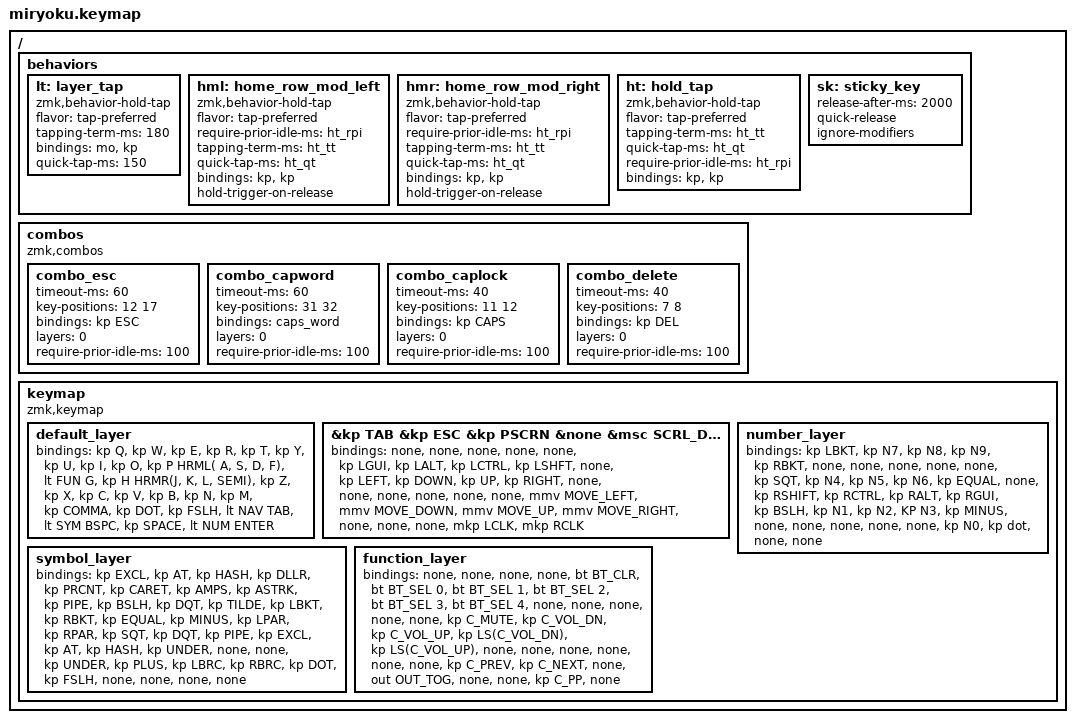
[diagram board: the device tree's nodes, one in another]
#define ZMK_POINTING_DEFAULT_MOVE_VAL 800
#define ZMK_POINTING_DEFAULT_SCRL_VAL 10

#include <behaviors.dtsi>
#include <dt-bindings/zmk/keys.h>
#include <dt-bindings/zmk/bt.h>
#include <dt-bindings/zmk/outputs.h>
#include <dt-bindings/zmk/pointing.h>

// Define layers
#define NAV 1
#define NUM  2
#define SYM 3
#define FUN 4

// Home row mods macro
#define HRML(k1,k2,k3,k4) &hml LGUI k1  &hml LALT k2  &hml LCTRL k3  &hml LSHFT k4
#define HRMR(k1,k2,k3,k4) &hmr RSHFT k1  &hmr RCTRL k2  &hmr RALT k3  &hmr RGUI k4

#define ht_tt 200
#define ht_qt 125
#define ht_rpi 100

/ {
    behaviors {
        lt: layer_tap {
            compatible = "zmk,behavior-hold-tap";
            #binding-cells = <2>;
            flavor = "tap-preferred";
            tapping-term-ms = <180>;
            bindings = <&mo>, <&kp>;
            quick-tap-ms = <150>;
        };

        hml: home_row_mod_left {
            compatible = "zmk,behavior-hold-tap";
            #binding-cells = <2>;
            flavor = "tap-preferred";
            require-prior-idle-ms = <ht_rpi>;
            tapping-term-ms = <ht_tt>;
            quick-tap-ms = <ht_qt>;
            bindings = <&kp>, <&kp>;
            hold-trigger-on-release;
        };
        hmr: home_row_mod_right {
            compatible = "zmk,behavior-hold-tap";
            #binding-cells = <2>;
            flavor = "tap-preferred";
            require-prior-idle-ms = <ht_rpi>;
            tapping-term-ms = <ht_tt>;
            quick-tap-ms = <ht_qt>;
            bindings = <&kp>, <&kp>;
            hold-trigger-on-release;
        };
        //I used for prior version of mod tap
        ht: hold_tap {
            compatible = "zmk,behavior-hold-tap";
            #binding-cells = <2>;
            flavor = "tap-preferred";
            tapping-term-ms = <ht_tt>;
            quick-tap-ms = <ht_qt>;
            require-prior-idle-ms = <ht_rpi>;
            bindings = <&kp>, <&kp>;
        };
        sk: sticky_key {
            release-after-ms = <2000>;
            quick-release;
            ignore-modifiers;
        };
    };
    combos {
        compatible = "zmk,combos";
        combo_esc {
            timeout-ms = <60>;
            key-positions = <12 17>;
            bindings = <&kp ESC>;
            layers = <0>;
            require-prior-idle-ms = <100>;
        };
        combo_capword{
            timeout-ms = <60>;
            key-positions = <31 32>;
            bindings = <&caps_word>;
            layers = <0>;
            require-prior-idle-ms = <100>;
        };
        combo_caplock {
            timeout-ms = <40>;
            key-positions = <11 12>;
            bindings = <&kp CAPS>;
            layers = <0>;
            require-prior-idle-ms = <100>;
        };
        combo_delete{
            timeout-ms = <40>;
            key-positions = <7 8>;
            bindings = <&kp DEL>;
            layers = <0>;
            require-prior-idle-ms = <100>;
        };
    };

    keymap {
        compatible = "zmk,keymap";
        default_layer {
            bindings = <
                //╭──────────┬──────────┬──────────┬──────────┬──────────╮   ╭──────────┬──────────┬──────────┬──────────┬──────────╮
                //│  Q       │  W       │  E       │  R       │  T       │   │  Y       │  U       │  I       │  O       │   P      │
                    &kp Q      &kp W      &kp E      &kp R      &kp T          &kp Y      &kp U     &kp I        &kp O      &kp P 
                //├──────────┼──────────┼──────────┼──────────┼──────────┤   ├──────────┼──────────┼──────────┼──────────┼──────────┤
                //│  A       │  S       │  D       │  F       │  G       │   │  H       │  J       │  K       │  L       │  ; :     │
                    HRML( A,     S,        D,           F)      &lt FUN G     &kp H      HRMR(J,      K,        L,         SEMI)
                //├──────────┼──────────┼──────────┼──────────┼──────────┤   ├──────────┼──────────┼──────────┼──────────┼──────────┤
                //│  Z       │  X       │  C       │  V       │  B       │   │  N       │  M       │ , <      │ . >      │ / ?      │
                    &kp Z       &kp X      &kp C      &kp V      &kp B          &kp N      &kp M      &kp COMMA  &kp DOT    &kp FSLH
                //╰──────────┴──────────┴──────────┼──────────┼──────────┤   ├──────────┼──────────┼──────────┴──────────┴──────────╯
                                                   &lt NAV TAB &lt SYM BSPC   &kp SPACE &lt NUM ENTER
                //                                 ╰──────────┴──────────╯   ╰──────────┴──────────╯
            >;
        };
         
                   &kp LA(TAB)  &kp TAB    &kp ESC   &kp PSCRN  &none        &msc SCRL_DOWN &kp PG_DN &kp PG_UP &msc SCRL_UP &kp DEL
        navigation_layer {
            bindings = <
                //╭──────────┬──────────┬──────────┬──────────┬──────────╮   ╭──────────┬──────────┬──────────┬──────────┬──────────╮
                //│ ALT+TAB  │   TAB    │   ESC    │   PTS    │          │   │  HOME    │  PG_DN   │ PG_UP    │  S_UP    │   DEL    │
                    &none       &none      &none      &none     &none          
                //├──────────┼──────────┼──────────┼──────────┼──────────┤   ├──────────┼──────────┼──────────┼──────────┼──────────┤
                //│          │          │          │          │          │   │   left   │  down    │   up     │  right   │          │
                    &kp LGUI   &kp LALT   &kp LCTRL  &kp LSHFT  &none          &kp LEFT   &kp DOWN   &kp UP     &kp RIGHT   &none
                //├──────────┼──────────┼──────────┼──────────┼──────────┤   ├──────────┼──────────┼──────────┼──────────┼──────────┤
                //│          │          │          │          │          │   │ m left   │ m down   │  m up    │ m  right │  ENTER   │
                     &none      &none      &none      &none       &none  &mmv MOVE_LEFT &mmv MOVE_DOWN &mmv MOVE_UP &mmv MOVE_RIGHT  &none
                //╰──────────┴──────────┴──────────┼──────────┼──────────┤   ├──────────┼──────────┼──────────┴──────────┴──────────╯
                                                      &none       &none        &mkp LCLK  &mkp RCLK
            //                                     ╰──────────┴──────────╯   ╰──────────┴──────────╯
            >;
        };       
        
        number_layer {
            bindings = <
                //╭──────────┬──────────┬──────────┬──────────┬──────────╮   ╭──────────┬──────────┬──────────┬──────────┬──────────╮
                //│    [     │    7     │    8     │    9     │    ]     │   │          │          │          │          │          │
                    &kp LBKT    &kp N7     &kp N8     &kp N9    &kp RBKT        &none      &none      &none      &none      &none
                //├──────────┼──────────┼──────────┼──────────┼──────────┤   ├──────────┼──────────┼──────────┼──────────┼──────────┤
                //│    '     │    4     │    5     │    6     │    =     │   │          │          │          │          │          │
                    &kp SQT     &kp N4     &kp N5     &kp N6    &kp EQUAL       &none    &kp RSHIFT  &kp RCTRL  &kp RALT   &kp RGUI
                //├──────────┼──────────┼──────────┼──────────┼──────────┤   ├──────────┼──────────┼──────────┼──────────┼──────────┤
                //│     \    │    1     │    2     │    3     │    -     │   │          │          │          │          │          │
                    &kp BSLH    &kp N1     &kp N2     &KP N3    &kp MINUS       &none      &none      &none      &none      &none
                //╰──────────┴──────────┴──────────┼──────────┼──────────┤   ├──────────┼──────────┼──────────┴──────────┴──────────╯
                                                     &kp N0     &kp dot         &none       &none
                //                                 ╰──────────┴──────────╯   ╰──────────┴──────────╯
            >;
        };

        symbol_layer {
            bindings = <
                //╭──────────┬──────────┬──────────┬──────────┬──────────╮   ╭──────────┬──────────┬──────────┬──────────┬──────────╮
                //│     !    │    @     │    #     │    $     │    %     │   │    ^     │    &     │     *    │    |     │    \     │
                    &kp EXCL   &kp AT     &kp HASH   &kp DLLR   &kp PRCNT      &kp CARET  &kp AMPS   &kp ASTRK  &kp PIPE    &kp BSLH
                //├──────────┼──────────┼──────────┼──────────┼──────────┤   ├──────────┼──────────┼──────────┼──────────┼──────────┤
                //│    `     │    ~     │    [     │    ]     │    =     │   │    -     │    (     │    )     │    '     │    "     │
                    &kp DQT     &kp TILDE  &kp LBKT   &kp RBKT   &kp EQUAL      &kp MINUS  &kp LPAR   &kp RPAR   &kp SQT    &kp DQT //├──────────┼──────────┼──────────┼──────────┼──────────┤   ├──────────┼──────────┼──────────┼──────────┼──────────┤
                //│          │          │          │          │    _     │   │    +     │    {     │    }     │    .     │    /     │
                    &kp PIPE   &kp EXCL    &kp AT    &kp HASH   &kp UNDER       &none      &none    &kp UNDER      &kp PLUS   &kp LBRC    &kp RBRC   &kp DOT    &kp FSLH
                //╰──────────┴──────────┴──────────┼──────────┼──────────┤   ├──────────┼──────────┼──────────┴──────────┴──────────╯
                                                       &none     &none         &none       &none
                //                                 ╰──────────┴──────────╯   ╰──────────┴──────────╯
            >;
        };

        function_layer {
            bindings = <
                //╭──────────┬──────────┬──────────┬──────────┬──────────╮   ╭──────────┬──────────┬──────────┬──────────┬──────────╮
                //│          │          │          │          │          │   │          │          │          │          │          │
                    &none       &none      &none      &none    &bt BT_CLR  &bt BT_SEL 0 &bt BT_SEL 1 &bt BT_SEL 2 &bt BT_SEL 3 &bt BT_SEL 4
                //├──────────┼──────────┼──────────┼──────────┼──────────┤   ├──────────┼──────────┼──────────┼──────────┼──────────┤
                //│          │          │          │          │          │   │          │          │          │          │          │
                     &none      &none     &none       &none      &none       &kp C_MUTE &kp C_VOL_DN &kp C_VOL_UP &kp LS(C_VOL_DN) &kp LS(C_VOL_UP)
                //├──────────┼──────────┼──────────┼──────────┼──────────┤   ├──────────┼──────────┼──────────┼──────────┼──────────┤
                //│          │          │          │          │          │   │          │          │          │          │          │
                    &none       &none      &none      &none      &none         &none    &kp C_PREV  &kp C_NEXT  &none     &out OUT_TOG
                //╰──────────┴──────────┴──────────┼──────────┼──────────┤   ├──────────┼──────────┼──────────┴──────────┴──────────╯
                                                     &none      &none          &kp C_PP    &none 
                //                                 ╰──────────┴──────────╯   ╰──────────┴──────────╯
            >;
        };
    };
};
